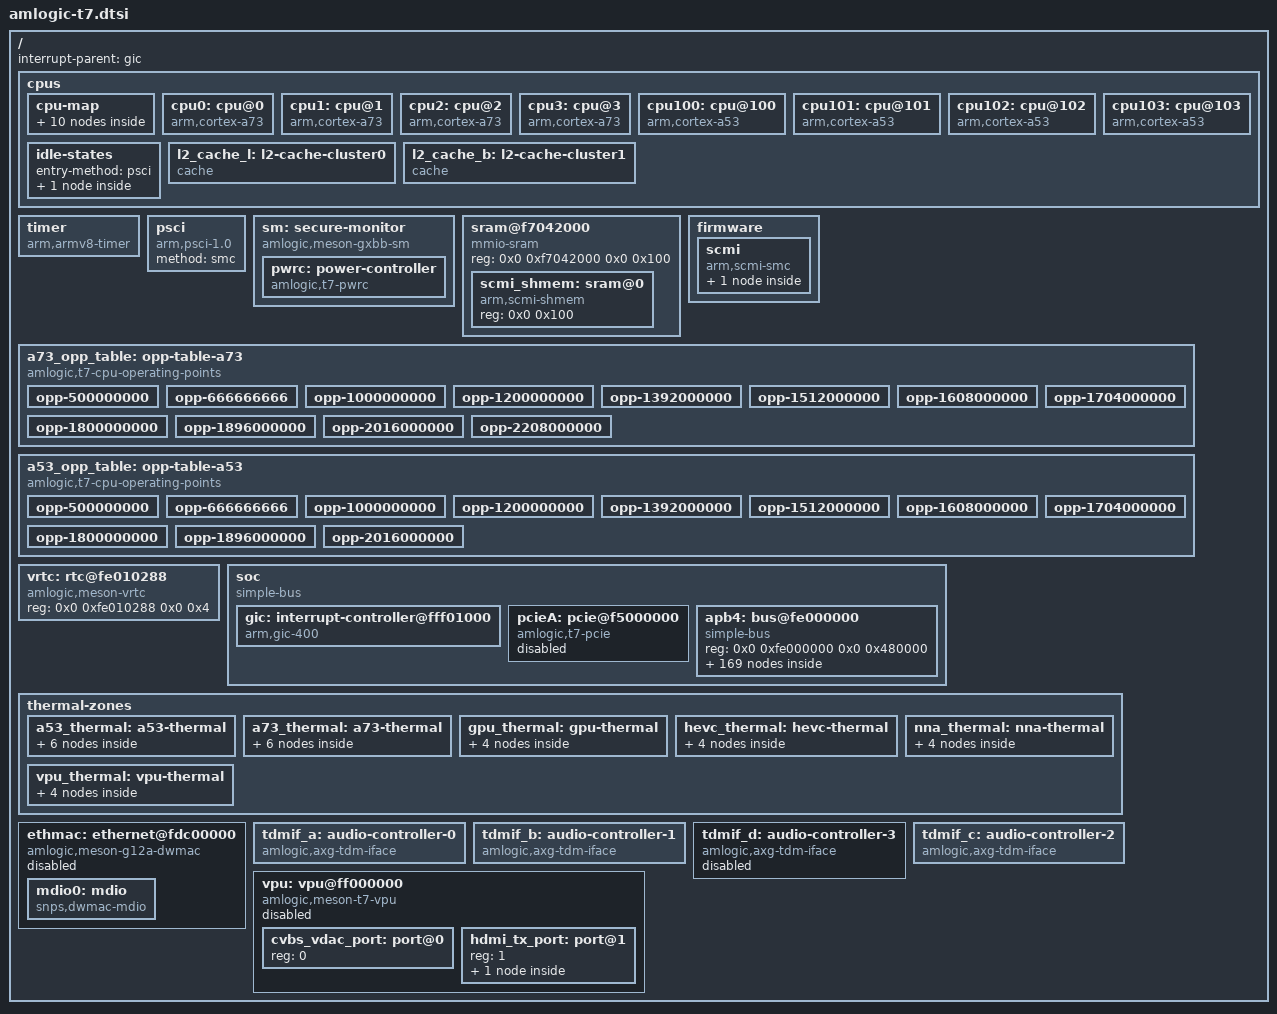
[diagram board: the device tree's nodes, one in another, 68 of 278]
// SPDX-License-Identifier: (GPL-2.0+ OR MIT)
/*
 * Copyright (c) 2019 Amlogic, Inc. All rights reserved.
 */

#include <dt-bindings/interrupt-controller/arm-gic.h>
#include <dt-bindings/gpio/gpio.h>
#include <dt-bindings/gpio/amlogic,t7-periphs-pinctrl.h>
#include <dt-bindings/power/amlogic,t7-pwrc.h>
#include "amlogic-t7-reset.h"
#include <dt-bindings/clock/amlogic,t7-scmi.h>
#include <dt-bindings/clock/amlogic,t7-cpu-clkc.h>
#include <dt-bindings/clock/amlogic,t7-pll-clkc.h>
#include <dt-bindings/clock/amlogic,t7-peripherals-clkc.h>
#include <dt-bindings/thermal/thermal.h>
#include <dt-bindings/phy/phy.h>
#include <dt-bindings/clock/axg-audio-clkc.h>
#include <dt-bindings/reset/amlogic,meson-axg-audio-arb.h>
#include <dt-bindings/reset/amlogic,meson-g12a-audio-reset.h>
#include <dt-bindings/sound/meson-g12a-tohdmitx.h>

/ {
	interrupt-parent = <&gic>;
	#address-cells = <2>;
	#size-cells = <2>;

	cpus {
		#address-cells = <0x2>;
		#size-cells = <0x0>;

		cpu-map {
			cluster0 {
				core0 {
					cpu = <&cpu0>;
				};
				core1 {
					cpu = <&cpu1>;
				};
				core2 {
					cpu = <&cpu2>;
				};
				core3 {
					cpu = <&cpu3>;
				};
			};

			cluster1 {
				core0 {
					cpu = <&cpu100>;
				};
				core1 {
					cpu = <&cpu101>;
				};
				core2 {
					cpu = <&cpu102>;
				};
				core3 {
					cpu = <&cpu103>;
				};
			};
		};

		cpu0: cpu@0 {
			device_type = "cpu";
			compatible = "arm,cortex-a73";
			reg = <0x0 0x0>;
			enable-method = "psci";
			cpu-idle-states = <&cpu_sleep>;
			clocks = <&cpu_clkc CLKID_A73_CPU>;
			capacity-dmips-mhz = <1024>;
			dynamic-power-coefficient = <550>;
			d-cache-line-size = <64>;
			d-cache-size = <0x10000>;
			d-cache-sets = <64>;
			i-cache-line-size = <64>;
			i-cache-size = <0x10000>;
			i-cache-sets = <64>;
			next-level-cache = <&l2_cache_b>;
			#cooling-cells = <2>;
		};

		cpu1: cpu@1 {
			device_type = "cpu";
			compatible = "arm,cortex-a73";
			reg = <0x0 0x1>;
			enable-method = "psci";
			cpu-idle-states = <&cpu_sleep>;
			clocks = <&cpu_clkc CLKID_A73_CPU>;
			capacity-dmips-mhz = <1024>;
			dynamic-power-coefficient = <550>;
			d-cache-line-size = <64>;
			d-cache-size = <0x10000>;
			d-cache-sets = <64>;
			i-cache-line-size = <64>;
			i-cache-size = <0x10000>;
			i-cache-sets = <64>;
			next-level-cache = <&l2_cache_b>;
			#cooling-cells = <2>;
		};

		cpu2: cpu@2 {
			device_type = "cpu";
			compatible = "arm,cortex-a73";
			reg = <0x0 0x2>;
			enable-method = "psci";
			cpu-idle-states = <&cpu_sleep>;
			clocks = <&cpu_clkc CLKID_A73_CPU>;
			capacity-dmips-mhz = <1024>;
			dynamic-power-coefficient = <550>;
			d-cache-line-size = <64>;
			d-cache-size = <0x10000>;
			d-cache-sets = <64>;
			i-cache-line-size = <64>;
			i-cache-size = <0x10000>;
			i-cache-sets = <64>;
			next-level-cache = <&l2_cache_b>;
			#cooling-cells = <2>;
		};

		cpu3: cpu@3 {
			device_type = "cpu";
			compatible = "arm,cortex-a73";
			reg = <0x0 0x3>;
			enable-method = "psci";
			cpu-idle-states = <&cpu_sleep>;
			clocks = <&cpu_clkc CLKID_A73_CPU>;
			capacity-dmips-mhz = <1024>;
			dynamic-power-coefficient = <550>;
			d-cache-line-size = <64>;
			d-cache-size = <0x10000>;
			d-cache-sets = <64>;
			i-cache-line-size = <64>;
			i-cache-size = <0x10000>;
			i-cache-sets = <64>;
			next-level-cache = <&l2_cache_b>;
			#cooling-cells = <2>;
		};

		cpu100: cpu@100 {
			device_type = "cpu";
			compatible = "arm,cortex-a53";
			reg = <0x0 0x100>;
			enable-method = "psci";
			cpu-idle-states = <&cpu_sleep>;
			clocks = <&cpu_clkc CLKID_A53_CPU>;
			capacity-dmips-mhz = <632>;
			dynamic-power-coefficient = <110>;
			d-cache-line-size = <32>;
			d-cache-size = <0x8000>;
			d-cache-sets = <32>;
			i-cache-line-size = <32>;
			i-cache-size = <0x8000>;
			i-cache-sets = <32>;
			next-level-cache = <&l2_cache_l>;
			#cooling-cells = <2>;
		};

		cpu101: cpu@101 {
			device_type = "cpu";
			compatible = "arm,cortex-a53";
			reg = <0x0 0x101>;
			enable-method = "psci";
			cpu-idle-states = <&cpu_sleep>;
			clocks = <&cpu_clkc CLKID_A53_CPU>;
			capacity-dmips-mhz = <632>;
			dynamic-power-coefficient = <110>;
			d-cache-line-size = <32>;
			d-cache-size = <0x8000>;
			d-cache-sets = <32>;
			i-cache-line-size = <32>;
			i-cache-size = <0x8000>;
			i-cache-sets = <32>;
			next-level-cache = <&l2_cache_l>;
			#cooling-cells = <2>;
		};

		cpu102: cpu@102 {
			device_type = "cpu";
			compatible = "arm,cortex-a53";
			reg = <0x0 0x102>;
			enable-method = "psci";
			cpu-idle-states = <&cpu_sleep>;
			clocks = <&cpu_clkc CLKID_A53_CPU>;
			capacity-dmips-mhz = <632>;
			dynamic-power-coefficient = <110>;
			d-cache-line-size = <32>;
			d-cache-size = <0x8000>;
			d-cache-sets = <32>;
			i-cache-line-size = <32>;
			i-cache-size = <0x8000>;
			i-cache-sets = <32>;
			next-level-cache = <&l2_cache_l>;
			#cooling-cells = <2>;
		};

		cpu103: cpu@103 {
			device_type = "cpu";
			compatible = "arm,cortex-a53";
			reg = <0x0 0x103>;
			enable-method = "psci";
			cpu-idle-states = <&cpu_sleep>;
			clocks = <&cpu_clkc CLKID_A53_CPU>;
			capacity-dmips-mhz = <632>;
			dynamic-power-coefficient = <110>;
			d-cache-line-size = <32>;
			d-cache-size = <0x8000>;
			d-cache-sets = <32>;
			i-cache-line-size = <32>;
			i-cache-size = <0x8000>;
			i-cache-sets = <32>;
			next-level-cache = <&l2_cache_l>;
			#cooling-cells = <2>;
		};

		idle-states {
			entry-method = "psci";

			cpu_sleep: cpu-sleep {
				compatible = "arm,idle-state";
				/* Power-down entry/exit has not been verified on VIM4. */
				status = "disabled";
				arm,psci-suspend-param = <0x10000>;
				local-timer-stop;
				entry-latency-us = <4000>;
				exit-latency-us = <5000>;
				min-residency-us = <10000>;
			};
		};

		l2_cache_l: l2-cache-cluster0 {
			compatible = "cache";
			cache-level = <2>;
			cache-unified;
			cache-size = <0x40000>;  /* L2. 256 KB */
			cache-line-size = <64>;
			cache-sets = <512>;
		};

		l2_cache_b: l2-cache-cluster1 {
			compatible = "cache";
			cache-level = <2>;
			cache-unified;
			cache-size = <0x100000>; /* L2. 1 Mb */
			cache-line-size = <64>;
			cache-sets = <512>;
		};
	};

	timer {
		compatible = "arm,armv8-timer";
		interrupts = <GIC_PPI 13 (GIC_CPU_MASK_SIMPLE(8) | IRQ_TYPE_LEVEL_LOW)>,
			     <GIC_PPI 14 (GIC_CPU_MASK_SIMPLE(8) | IRQ_TYPE_LEVEL_LOW)>,
			     <GIC_PPI 11 (GIC_CPU_MASK_SIMPLE(8) | IRQ_TYPE_LEVEL_LOW)>,
			     <GIC_PPI 10 (GIC_CPU_MASK_SIMPLE(8) | IRQ_TYPE_LEVEL_LOW)>;
	};

	psci {
		compatible = "arm,psci-1.0";
		method = "smc";
	};

	sm: secure-monitor {
		compatible = "amlogic,meson-gxbb-sm";

		pwrc: power-controller {
			compatible = "amlogic,t7-pwrc";
			#power-domain-cells = <1>;
		};
	};

	sram@f7042000 {
		compatible = "mmio-sram";
		reg = <0x0 0xf7042000 0x0 0x100>;
		#address-cells = <1>;
		#size-cells = <1>;
		ranges = <0 0x0 0xf7042000 0x100>;

		scmi_shmem: sram@0 {
			compatible = "arm,scmi-shmem";
			reg = <0x0 0x100>;
		};
	};

	firmware {
		scmi: scmi {
			compatible = "arm,scmi-smc";
			arm,smc-id = <0x820000c1>;
			shmem = <&scmi_shmem>;
			#address-cells = <1>;
			#size-cells = <0>;

			scmi_clk: protocol@14 {
				reg = <0x14>;
				#clock-cells = <1>;
			};
		};
	};

	a73_opp_table: opp-table-a73 {
		compatible = "amlogic,t7-cpu-operating-points";
		amlogic,secure-monitor = <&sm>;
		opp-shared;

		opp-500000000 {
			opp-hz = /bits/ 64 <500000000>;
			opp-microvolt = <819000>;
			opp-microvolt-bin2 = <799000>;
			opp-microvolt-bin3 = <789000>;
			clock-latency-ns = <50000>;
		};

		opp-666666666 {
			opp-hz = /bits/ 64 <666666666>;
			opp-microvolt = <819000>;
			opp-microvolt-bin2 = <799000>;
			opp-microvolt-bin3 = <789000>;
			clock-latency-ns = <50000>;
		};

		opp-1000000000 {
			opp-hz = /bits/ 64 <1000000000>;
			opp-microvolt = <819000>;
			opp-microvolt-bin2 = <799000>;
			opp-microvolt-bin3 = <789000>;
			clock-latency-ns = <50000>;
		};

		opp-1200000000 {
			opp-hz = /bits/ 64 <1200000000>;
			opp-microvolt = <819000>;
			opp-microvolt-bin2 = <799000>;
			opp-microvolt-bin3 = <789000>;
			clock-latency-ns = <50000>;
		};

		opp-1392000000 {
			opp-hz = /bits/ 64 <1392000000>;
			opp-microvolt = <819000>;
			opp-microvolt-bin2 = <809000>;
			opp-microvolt-bin3 = <809000>;
			clock-latency-ns = <50000>;
		};

		opp-1512000000 {
			opp-hz = /bits/ 64 <1512000000>;
			opp-microvolt = <829000>;
			opp-microvolt-bin2 = <809000>;
			opp-microvolt-bin3 = <809000>;
			clock-latency-ns = <50000>;
		};

		opp-1608000000 {
			opp-hz = /bits/ 64 <1608000000>;
			opp-microvolt = <849000>;
			opp-microvolt-bin2 = <829000>;
			opp-microvolt-bin3 = <819000>;
			clock-latency-ns = <50000>;
		};

		opp-1704000000 {
			opp-hz = /bits/ 64 <1704000000>;
			opp-microvolt = <869000>;
			opp-microvolt-bin2 = <849000>;
			opp-microvolt-bin3 = <829000>;
			clock-latency-ns = <50000>;
		};

		opp-1800000000 {
			opp-hz = /bits/ 64 <1800000000>;
			opp-microvolt = <909000>;
			opp-microvolt-bin2 = <859000>;
			opp-microvolt-bin3 = <849000>;
			clock-latency-ns = <50000>;
		};

		opp-1896000000 {
			opp-hz = /bits/ 64 <1896000000>;
			opp-microvolt = <939000>;
			opp-microvolt-bin2 = <889000>;
			opp-microvolt-bin3 = <859000>;
			clock-latency-ns = <50000>;
		};

		opp-2016000000 {
			opp-hz = /bits/ 64 <2016000000>;
			opp-microvolt = <959000>;
			opp-microvolt-bin2 = <919000>;
			opp-microvolt-bin3 = <879000>;
			clock-latency-ns = <50000>;
		};

		opp-2208000000 {
			opp-hz = /bits/ 64 <2208000000>;
			opp-microvolt = <1009000>;
			opp-microvolt-bin2 = <969000>;
			opp-microvolt-bin3 = <919000>;
			clock-latency-ns = <50000>;
		};
	};

	a53_opp_table: opp-table-a53 {
		compatible = "amlogic,t7-cpu-operating-points";
		amlogic,secure-monitor = <&sm>;
		opp-shared;

		opp-500000000 {
			opp-hz = /bits/ 64 <500000000>;
			opp-microvolt = <769000>;
			opp-microvolt-bin2 = <759000>;
			opp-microvolt-bin3 = <749000>;
			clock-latency-ns = <50000>;
		};

		opp-666666666 {
			opp-hz = /bits/ 64 <666666666>;
			opp-microvolt = <769000>;
			opp-microvolt-bin2 = <759000>;
			opp-microvolt-bin3 = <749000>;
			clock-latency-ns = <50000>;
		};

		opp-1000000000 {
			opp-hz = /bits/ 64 <1000000000>;
			opp-microvolt = <769000>;
			opp-microvolt-bin2 = <759000>;
			opp-microvolt-bin3 = <749000>;
			clock-latency-ns = <50000>;
		};

		opp-1200000000 {
			opp-hz = /bits/ 64 <1200000000>;
			opp-microvolt = <769000>;
			opp-microvolt-bin2 = <759000>;
			opp-microvolt-bin3 = <749000>;
			clock-latency-ns = <50000>;
		};

		opp-1392000000 {
			opp-hz = /bits/ 64 <1392000000>;
			opp-microvolt = <769000>;
			opp-microvolt-bin2 = <769000>;
			opp-microvolt-bin3 = <769000>;
			clock-latency-ns = <50000>;
		};

		opp-1512000000 {
			opp-hz = /bits/ 64 <1512000000>;
			opp-microvolt = <809000>;
			opp-microvolt-bin2 = <789000>;
			opp-microvolt-bin3 = <779000>;
			clock-latency-ns = <50000>;
		};

		opp-1608000000 {
			opp-hz = /bits/ 64 <1608000000>;
			opp-microvolt = <839000>;
			opp-microvolt-bin2 = <799000>;
			opp-microvolt-bin3 = <789000>;
			clock-latency-ns = <50000>;
		};

		opp-1704000000 {
			opp-hz = /bits/ 64 <1704000000>;
			opp-microvolt = <869000>;
			opp-microvolt-bin2 = <829000>;
			opp-microvolt-bin3 = <809000>;
			clock-latency-ns = <50000>;
		};

		opp-1800000000 {
			opp-hz = /bits/ 64 <1800000000>;
			opp-microvolt = <909000>;
			opp-microvolt-bin2 = <859000>;
			opp-microvolt-bin3 = <829000>;
			clock-latency-ns = <50000>;
		};

		opp-1896000000 {
			opp-hz = /bits/ 64 <1896000000>;
			opp-microvolt = <949000>;
			opp-microvolt-bin2 = <899000>;
			opp-microvolt-bin3 = <859000>;
			clock-latency-ns = <50000>;
		};

		opp-2016000000 {
			opp-hz = /bits/ 64 <2016000000>;
			opp-microvolt = <1009000>;
			opp-microvolt-bin2 = <949000>;
			opp-microvolt-bin3 = <919000>;
			clock-latency-ns = <50000>;
		};
	};

	vrtc: rtc@fe010288 {
		compatible = "amlogic,meson-vrtc";
		reg = <0x0 0xfe010288 0x0 0x4>;
	};

	soc {
		compatible = "simple-bus";
		#address-cells = <2>;
		#size-cells = <2>;
		ranges;

		gic: interrupt-controller@fff01000 {
			compatible = "arm,gic-400";
			#interrupt-cells = <3>;
			#address-cells = <0>;
			interrupt-controller;
			reg = <0x0 0xfff01000 0 0x1000>,
			      <0x0 0xfff02000 0 0x2000>,
			      <0x0 0xfff04000 0 0x2000>,
			      <0x0 0xfff06000 0 0x2000>;
			interrupts = <GIC_PPI 9 (GIC_CPU_MASK_SIMPLE(8) | IRQ_TYPE_LEVEL_HIGH)>;
		};

		pcieA: pcie@f5000000 {
			compatible = "amlogic,t7-pcie", "snps,dw-pcie";
			reg = <0x0 0xf5000000 0x0 0x400000>,
			      <0x0 0xfe02c000 0x0 0x2000>,
			      <0x0 0xf5400000 0x0 0x200000>;
			reg-names = "dbi", "cfg", "config";
			interrupts = <GIC_SPI 141 IRQ_TYPE_LEVEL_HIGH>;
			interrupt-names = "msi";
			#interrupt-cells = <1>;
			interrupt-map-mask = <0 0 0 0>;
			interrupt-map = <0 0 0 0 &gic GIC_SPI 143 IRQ_TYPE_EDGE_RISING>;
			bus-range = <0x0 0xff>;
			#address-cells = <3>;
			#size-cells = <2>;
			device_type = "pci";
			ranges = <0x81000000 0x0 0x0 0x0 0xf5600000 0x0 0x100000>,
				 <0x82000000 0x0 0xf5700000 0x0 0xf5700000 0x0 0x1900000>;

			clocks = <&clkc_periphs CLKID_SYS_PCIE_PHY>, <&clkc_periphs CLKID_SYS_PCIE>,
				 <&pcie CLKID_PCIE_PLL>;
			clock-names = "general", "pclk", "port";
			power-domains = <&pwrc PWRC_T7_PCIE_ID>;
			resets = <&reset RESET_PCIE_A>,
				 <&reset RESET_PCIE_APB>;
			reset-names = "port",
				      "apb";

			dma-ranges = <0x02000000 0x0 0x0 0x0 0X0 0x0 0xe0000000>;
			num-lanes = <1>;
			phys = <&pcie_phy PHY_TYPE_PCIE>;
			phy-names = "pcie";
			status = "disabled";
		};

		apb4: bus@fe000000 {
			compatible = "simple-bus";
			reg = <0x0 0xfe000000 0x0 0x480000>;
			#address-cells = <2>;
			#size-cells = <2>;
			ranges = <0x0 0x0 0x0 0xfe000000 0x0 0x480000>,
				 <0x0 0xfdd00000 0x0 0xfdd00000 0x0 0x200000>; /* usb drd */

			rng: rng@440788 {
				compatible = "amlogic,meson-s4-rng";
				reg = <0x0 0x440788 0x0 0xc>;
			};

			clkc_periphs: clock-controller@0 {
				compatible = "amlogic,t7-peripherals-clkc";
				reg = <0x0 0x0 0x0 0x1c8>;
				#clock-cells = <1>;
				clocks = <&xtal>,
					 <&scmi_clk CLKID_SYS_CLK>,
					 <&scmi_clk CLKID_FIXED_PLL>,
					 <&scmi_clk CLKID_FCLK_DIV2>,
					 <&scmi_clk CLKID_FCLK_DIV2P5>,
					 <&scmi_clk CLKID_FCLK_DIV3>,
					 <&scmi_clk CLKID_FCLK_DIV4>,
					 <&scmi_clk CLKID_FCLK_DIV5>,
					 <&scmi_clk CLKID_FCLK_DIV7>,
					 <&hifi CLKID_HIFI_PLL>,
					 <&gp0 CLKID_GP0_PLL>,
					 <&gp1 CLKID_GP1_PLL>,
					 <&mpll CLKID_MPLL1>,
					 <&mpll CLKID_MPLL2>,
					 <&mpll CLKID_MPLL3>;
				clock-names = "xtal",
					      "sys",
					      "fix",
					      "fdiv2",
					      "fdiv2p5",
					      "fdiv3",
					      "fdiv4",
					      "fdiv5",
					      "fdiv7",
					      "hifi",
					      "gp0",
					      "gp1",
					      "mpll1",
					      "mpll2",
					      "mpll3";
			};

			reset: reset-controller@2000 {
				compatible = "amlogic,t7-reset";
				reg = <0x0 0x2000 0x0 0x98>;
				#reset-cells = <1>;
			};

			watchdog@2100 {
				compatible = "amlogic,t7-wdt";
				reg = <0x0 0x2100 0x0 0x10>;
				clocks = <&xtal>;
			};

			saradc: adc@26000 {
				compatible = "amlogic,meson-g12a-saradc",
					     "amlogic,meson-saradc";
				reg = <0x0 0x26000 0x0 0x48>;
				interrupts = <GIC_SPI 181 IRQ_TYPE_EDGE_RISING>;
				#io-channel-cells = <1>;
				clocks = <&xtal>, <&clkc_periphs CLKID_SYS_SAR_ADC>,
					 <&clkc_periphs CLKID_SARADC>,
					 <&clkc_periphs CLKID_SARADC_SEL>;
				clock-names = "clkin", "core", "adc_clk", "adc_sel";
				status = "disabled";
			};

			spifc: spi@56000 {
				compatible = "amlogic,meson-gxbb-spifc";
				reg = <0x0 0x56000 0x0 0x80>;
				clocks = <&clkc_periphs CLKID_SYS_SPIFC>;
				#address-cells = <1>;
				#size-cells = <0>;
				status = "disabled";
			};

			ir: ir-receiver@84040 {
				compatible = "amlogic,meson-gxbb-ir";
				reg = <0x0 0x84040 0x0 0xa4>;
				interrupts = <GIC_SPI 22 IRQ_TYPE_EDGE_RISING>;
				status = "disabled";
			};

			periphs_pinctrl: pinctrl@4000 {
				compatible = "amlogic,t7-periphs-pinctrl";
				#address-cells = <2>;
				#size-cells = <2>;
				ranges;

				gpio: bank@4000 {
					reg = <0x0 0x4000 0x0 0x0064>,
					      <0x0 0x40c0 0x0 0x0220>;
					reg-names = "mux", "gpio";
					gpio-controller;
					#gpio-cells = <2>;
					gpio-ranges = <&periphs_pinctrl 0 0 157>;
				};

				emmc_ctrl_pins: emmc-ctrl {
					mux-0 {
						groups = "emmc_cmd";
						function = "emmc";
						bias-pull-up;
					};

					mux-1 {
						groups = "emmc_clk";
						function = "emmc";
						bias-disable;
					};
				};

				emmc_data_4b_pins: emmc-data-4b {
					mux {
						groups = "emmc_nand_d0",
							 "emmc_nand_d1",
							 "emmc_nand_d2",
							 "emmc_nand_d3";
						function = "emmc";
						bias-pull-up;
					};
				};

				emmc_data_8b_pins: emmc-data-8b {
					mux {
						groups = "emmc_nand_d0",
							 "emmc_nand_d1",
							 "emmc_nand_d2",
							 "emmc_nand_d3",
							 "emmc_nand_d4",
							 "emmc_nand_d5",
							 "emmc_nand_d6",
							 "emmc_nand_d7";
						function = "emmc";
						bias-pull-up;
					};
				};

				emmc_ds_pins: emmc-ds {
					mux {
						groups = "emmc_nand_ds";
						function = "emmc";
						bias-pull-down;
					};
				};

				emmc_clk_gate_pins: emmc-clk-gate {
					mux {
						groups = "GPIOB_8";
						function = "gpio_periphs";
						bias-pull-down;
					};
				};

				i2c0_ao_d_pins: i2c0-ao-d {
					mux {
						groups = "i2c0_ao_sck_d",
							 "i2c0_ao_sda_d";
						function = "i2c0_ao";
						bias-disable;
						drive-strength-microamp = <3000>;
					};
				};

				pwm_a_pins: pwm-a {
					mux {
						groups = "pwm_a";
						function = "pwm_a";
						bias-disable;
					};
				};

				pwm_ao_a_pins: pwm-ao-a {
					mux {
						groups = "pwm_ao_a";
						function = "pwm_ao_a";
						bias-disable;
					};
				};

				pwm_ao_b_pins: pwm-ao-b {
					mux {
						groups = "pwm_ao_b";
						function = "pwm_ao_b";
						bias-disable;
					};
				};

				pwm_ao_c_d_pins: pwm-ao-c-d {
					mux {
						groups = "pwm_ao_c_d";
						function = "pwm_ao_c";
						bias-disable;
					};
				};

				pwm_ao_c_e_pins: pwm-ao-c-e {
					mux {
						groups = "pwm_ao_c_e";
						function = "pwm_ao_c";
						bias-disable;
					};
				};

				pwm_ao_c_hiz_pins: pwm-ao-c-hiz {
					mux {
						groups = "pwm_ao_c_hiz";
						function = "pwm_ao_c_hiz";
						bias-disable;
					};
				};

				pwm_ao_d_pins: pwm-ao-d {
					mux {
						groups = "pwm_ao_d";
						function = "pwm_ao_d";
						bias-disable;
					};
				};

				pwm_ao_e_pins: pwm-ao-e {
					mux {
						groups = "pwm_ao_e";
						function = "pwm_ao_e";
						bias-disable;
					};
				};

				pwm_ao_f_pins: pwm-ao-f {
					mux {
						groups = "pwm_ao_f";
						function = "pwm_ao_f";
						bias-disable;
					};
				};

				pwm_ao_g_d11_pins: pwm-ao-g-d11 {
					mux {
						groups = "pwm_ao_g_d11";
						function = "pwm_ao_g";
						bias-disable;
					};
				};

				pwm_ao_g_d7_pins: pwm-ao-g-d7 {
					mux {
						groups = "pwm_ao_g_d7";
						function = "pwm_ao_g";
						bias-disable;
					};
				};

				pwm_ao_g_e_pins: pwm-ao-g-e {
					mux {
						groups = "pwm_ao_g_e";
						function = "pwm_ao_g";
						bias-disable;
					};
				};

				pwm_ao_g_hiz_pins: pwm-ao-g-hiz {
					mux {
						groups = "pwm_ao_g_hiz";
						function = "pwm_ao_g_hiz";
						bias-disable;
					};
				};

				pwm_ao_h_d5_pins: pwm-ao-h-d5 {
					mux {
						groups = "pwm_ao_h_d5";
						function = "pwm_ao_h";
						bias-disable;
					};
				};

				pwm_ao_h_d10_pins: pwm-ao-h-d10 {
					mux {
						groups = "pwm_ao_h_d10";
						function = "pwm_ao_h";
						bias-disable;
					};
				};

				pwm_b_pins: pwm-b {
					mux {
						groups = "pwm_b";
						function = "pwm_b";
						bias-disable;
					};
				};

				pwm_c_pins: pwm-c {
					mux {
						groups = "pwm_c";
						function = "pwm_c";
						bias-disable;
					};
				};

				pwm_d_pins: pwm-d {
					mux {
						groups = "pwm_d";
						function = "pwm_d";
						bias-disable;
					};
				};

				pwm_e_pins: pwm-e {
					mux {
						groups = "pwm_e";
						function = "pwm_e";
						bias-disable;
					};
				};

				pwm_f_pins: pwm-f {
					mux {
						groups = "pwm_f";
						function = "pwm_f";
						bias-disable;
					};
				};

				pwm_vs_y_pins: pwm-vs-y {
					mux {
						groups = "pwm_vs_y";
						function = "pwm_vs";
						bias-disable;
					};
				};

				pwm_vs_h_pins: pwm-vs-h {
					mux {
						groups = "pwm_vs_h";
						function = "pwm_vs";
						bias-disable;
					};
				};

				sdcard_pins: sdcard {
					mux {
						groups = "sdcard_d0",
							 "sdcard_d1",
							 "sdcard_d2",
							 "sdcard_d3",
							 "sdcard_clk",
							 "sdcard_cmd";
						function = "sdcard";
						bias-pull-up;
					};
				};

				sdcard_clk_gate_pins: sdcard-clk-gate {
					mux {
						groups = "GPIOC_4";
						function = "gpio_periphs";
						bias-pull-down;
					};
				};

				uart_c_pins: uart-c {
					mux {
						groups = "uart_c_tx",
							 "uart_c_rx",
							 "uart_c_cts",
							 "uart_c_rts";
						bias-pull-up;
						output-high;
						function = "uart_c";
					};
				};

				sdio_pins: sdio {
					mux {
						groups = "sdio_d0",
							 "sdio_d1",
							 "sdio_d2",
							 "sdio_d3",
							 "sdio_clk",
							 "sdio_cmd";
						function = "sdio";
						bias-pull-up;
					};
				};

				sdio_clk_gate_pins: sdio-clk-gate {
					mux {
						groups = "GPIOX_4";
						function = "gpio_periphs";
						bias-pull-up;
					};
				};

				eth_pins: eth {
					mux {
						groups = "eth_mdio",
							 "eth_mdc",
							 "eth_rgmii_rx_clk",
							 "eth_rx_dv",
							 "eth_rxd0",
							 "eth_rxd1",
							 "eth_txen",
							 "eth_txd0",
							 "eth_txd1";
						function = "eth";
						drive-strength-microamp = <4000>;
						bias-disable;
					};
				};

				eth_rgmii_pins: eth-rgmii {
					mux {
						groups = "eth_rxd2_rgmii",
							 "eth_rxd3_rgmii",
							 "eth_rgmii_tx_clk",
							 "eth_txd2_rgmii",
							 "eth_txd3_rgmii";
						function = "eth";
						drive-strength-microamp = <4000>;
						bias-disable;
					};
				};
			};

			gpio_intc: interrupt-controller@4080 {
				compatible = "amlogic,t7-gpio-intc",
					     "amlogic,meson-gpio-intc";
				reg = <0x0 0x4080 0x0 0x20>;
				interrupt-controller;
				#interrupt-cells = <2>;
				amlogic,channel-interrupts =
					<10 11 12 13 14 15 16 17 18 19 20 21>;
			};

			usb_comb: usb@3a000 {
				compatible = "amlogic,t7-usb-ctrl", "amlogic,meson-g12a-usb-ctrl";
				reg = <0x0 0x3a000 0x0 0xa0>;
				interrupts = <GIC_SPI 129 IRQ_TYPE_LEVEL_HIGH>;
				#address-cells = <2>;
				#size-cells = <2>;
				ranges = <0x0 0xfdd00000 0x0 0xfdd00000 0x0 0x200000>;

				clocks = <&clkc_periphs CLKID_SYS_USB>;
				resets = <&reset RESET_USB>;
				power-domains = <&pwrc PWRC_T7_USB_COMB_ID>;

				dr_mode = "otg";

				phys = <&usb2_phy0>, <&usb2_phy1>, <&usb3_phy PHY_TYPE_USB3>;
				phy-names = "usb2-phy0", "usb2-phy1", "usb3-phy0";

				status = "disabled";

				usb2_drd: usb@fdd00000 {
					compatible = "amlogic,t7-xhci";
					reg = <0x0 0xfdd00000 0x0 0x100000>;
					interrupts = <GIC_SPI 131 IRQ_TYPE_LEVEL_HIGH>;
					clocks = <&clkc_periphs CLKID_SYS_USB>;
					clock-names = "core";
				};

				usb3_drd: usb@fde00000 {
					compatible = "amlogic,t7-xhci";
					reg = <0x0 0xfde00000 0x0 0x100000>;
					interrupts = <GIC_SPI 130 IRQ_TYPE_LEVEL_HIGH>;
					clocks = <&clkc_periphs CLKID_SYS_USB>;
					clock-names = "core";
				};
			};

			usb2_phy0: phy@3c000 {
				compatible = "amlogic,t7-usb2-phy", "amlogic,g12a-usb2-phy";
				reg = <0x0 0x3c000 0x0 0x2000>;
				clocks = <&xtal>;
				clock-names = "xtal";
				resets = <&reset RESET_U2PHY20>;
				reset-names = "phy";
				#phy-cells = <0>;
			};

			usb2_phy1: phy@3e000 {
				compatible = "amlogic,t7-usb2-phy", "amlogic,g12a-usb2-phy";
				reg = <0x0 0x3e000 0x0 0x2000>;
				clocks = <&xtal>;
				clock-names = "xtal";
				resets = <&reset RESET_U2PHY21>;
				reset-names = "phy";
				#phy-cells = <0>;
			};

			usb3_phy: phy@62000 {
				compatible = "amlogic,t7-usb3-phy", "amlogic,g12a-usb3-pcie-phy";
				reg = <0x0 0x62000 0x0 0x2000>;
				clocks = <&pcie CLKID_PCIE_PLL>;
				clock-names = "ref_clk";
				resets = <&reset RESET_PCIE1_APB>;
				reset-names = "phy";
				assigned-clocks = <&pcie CLKID_PCIE_PLL>;
				assigned-clock-rates = <100000000>;
				#phy-cells = <1>;
			};

			uart_a: serial@78000 {
				compatible = "amlogic,t7-uart", "amlogic,meson-s4-uart";
				reg = <0x0 0x78000 0x0 0x18>;
				interrupts = <GIC_SPI 168 IRQ_TYPE_EDGE_RISING>;
				status = "disabled";
			};

			uart_c: serial@7c000 {
				compatible = "amlogic,t7-uart", "amlogic,meson-s4-uart";
				reg = <0x0 0x7c000 0x0 0x18>;
				interrupts = <GIC_SPI 170 IRQ_TYPE_EDGE_RISING>;
				clocks = <&xtal>, <&clkc_periphs CLKID_SYS_UART_C>, <&xtal>;
				clock-names = "xtal", "pclk", "baud";
				status = "disabled";
			};

			gpu: gpu@400000 {
				compatible = "amlogic,meson-g12a-mali", "arm,mali-bifrost";
				reg = <0x0 0x400000 0x0 0x4000>;
				interrupts = <GIC_SPI 146 IRQ_TYPE_LEVEL_HIGH>,
					     <GIC_SPI 145 IRQ_TYPE_LEVEL_HIGH>,
					     <GIC_SPI 144 IRQ_TYPE_LEVEL_HIGH>;
				interrupt-names = "job", "mmu", "gpu";
				clocks = <&clkc_periphs CLKID_MALI>,
					 <&clkc_periphs CLKID_SYS_MALI>;
				clock-names = "core", "bus";
				resets = <&reset RESET_MALI_CAPB3>, <&reset RESET_MALI>;
				power-domains = <&pwrc PWRC_T7_MALI_TOP_ID>;
				assigned-clocks = <&clkc_periphs CLKID_MALI_0_SEL>,
						  <&clkc_periphs CLKID_MALI_0>,
						  <&clkc_periphs CLKID_MALI>;
				assigned-clock-parents = <&scmi_clk CLKID_FCLK_DIV2P5>,
							 <0>,
							 <&clkc_periphs CLKID_MALI_0>;
				assigned-clock-rates = <0>, <800000000>, <0>;
				/* The GPU is IO-coherent (ACE-Lite) on T7 */
				dma-coherent;
				#cooling-cells = <2>;
				status = "disabled";
			};

			eth_phy: mdio-multiplexer@28000 {
				compatible = "amlogic,g12a-mdio-mux";
				reg = <0x0 0x28000 0x0 0xa4>;
				#address-cells = <1>;
				#size-cells = <0>;
				clocks = <&clkc_periphs CLKID_SYS_ETHPHY>,
					 <&xtal>,
					 <&scmi_clk CLKID_FCLK_50M>;
				clock-names = "pclk", "clkin0", "clkin1";
				mdio-parent-bus = <&mdio0>;

				ext_mdio: mdio@0 {
					reg = <0>;
					#address-cells = <1>;
					#size-cells = <0>;
				};

				int_mdio: mdio@1 {
					reg = <1>;
					#address-cells = <1>;
					#size-cells = <0>;

					internal_ephy: ethernet-phy@8 {
						compatible = "ethernet-phy-id0180.3301",
							     "ethernet-phy-ieee802.3-c22";
						interrupts = <GIC_SPI 340 IRQ_TYPE_LEVEL_HIGH>;
						reg = <8>;
						max-speed = <100>;
					};
				};
			};

			cpu_clkc: clock-controller@8000 {
				compatible = "amlogic,t7-cpu-clkc";
				reg = <0x0 0x8000 0x0 0x40>;
				clocks = <&xtal>,
					 <&scmi_clk CLKID_FCLK_DIV2>,
					 <&scmi_clk CLKID_FCLK_DIV3>,
					 <&scmi_clk CLKID_FCLK_DIV2P5>;
				clock-names = "xtal", "fclk_div2", "fclk_div3",
					      "fclk_div2p5";
				amlogic,secure-monitor = <&sm>;
				#clock-cells = <1>;
			};

			gp0: clock-controller@8080 {
				compatible = "amlogic,t7-gp0-pll";
				reg = <0x0 0x8080 0x0 0x20>;
				clocks = <&scmi_clk CLKID_TOP_PLL_OSC>;
				clock-names = "in0";
				#clock-cells = <1>;
			};

			gp1: clock-controller@80c0 {
				compatible = "amlogic,t7-gp1-pll";
				reg = <0x0 0x80c0 0x0 0x14>;
				clocks = <&scmi_clk CLKID_TOP_PLL_OSC>;
				clock-names = "in0";
				#clock-cells = <1>;
			};

			hifi: clock-controller@8100 {
				compatible = "amlogic,t7-hifi-pll";
				reg = <0x0 0x8100 0x0 0x20>;
				clocks = <&scmi_clk CLKID_TOP_PLL_OSC>;
				clock-names = "in0";
				#clock-cells = <1>;
			};

			pcie: clock-controller@8140 {
				compatible = "amlogic,t7-pcie-pll";
				reg = <0x0 0x8140 0x0 0x1c>;
				clocks = <&scmi_clk CLKID_PCIE_OSC>;
				clock-names = "in0";
				#clock-cells = <1>;
			};

			mpll: clock-controller@8180 {
				compatible = "amlogic,t7-mpll";
				reg = <0x0 0x8180 0x0 0x28>;
				clocks = <&scmi_clk CLKID_FIXED_PLL_DCO>;
				clock-names = "in0";
				#clock-cells = <1>;
			};

			hdmi: clock-controller@81c0 {
				compatible = "amlogic,t7-hdmi-pll";
				reg = <0x0 0x81c0 0x0 0x20>;
				clocks = <&scmi_clk CLKID_HDMI_PLL_OSC>;
				clock-names = "in0";
				#clock-cells = <1>;
			};

			mclk: clock-controller@8300 {
				compatible = "amlogic,t7-mclk-pll";
				reg = <0x0 0x8300 0x0 0x18>;
				clocks = <&scmi_clk CLKID_MCLK_PLL_OSC>,
					 <&xtal>,
					 <&scmi_clk CLKID_FCLK_50M>;
				clock-names = "in0", "in1", "in2";
				#clock-cells = <1>;
			};

			sec_ao: ao-secure@10220 {
				compatible = "amlogic,t7-ao-secure",
					     "amlogic,meson-gx-ao-secure",
					     "syscon";
				reg = <0x0 0x10220 0x0 0x140>;
				amlogic,has-chip-id;
			};

			a73_tsensor: temperature-sensor@20000 {
				compatible = "amlogic,t7-thermal";
				reg = <0x0 0x20000 0x0 0x50>;
				interrupts = <GIC_SPI 31 IRQ_TYPE_LEVEL_HIGH>;
				clocks = <&clkc_periphs CLKID_SYS_TS_A73>,
					 <&clkc_periphs CLKID_TS>;
				clock-names = "bus", "core";
				#thermal-sensor-cells = <0>;
				amlogic,secure-monitor = <&sm 1>;
			};

			a53_tsensor: temperature-sensor@22000 {
				compatible = "amlogic,t7-thermal";
				reg = <0x0 0x22000 0x0 0x50>;
				interrupts = <GIC_SPI 30 IRQ_TYPE_LEVEL_HIGH>;
				clocks = <&clkc_periphs CLKID_SYS_TS_A53>,
					 <&clkc_periphs CLKID_TS>;
				clock-names = "bus", "core";
				#thermal-sensor-cells = <0>;
				amlogic,secure-monitor = <&sm 2>;
			};

			pcie_phy: phy@2a000 {
				compatible = "amlogic,t7-pcie-phy", "amlogic,g12a-usb3-pcie-phy";
				reg = <0x0 0x2a000 0x0 0x2000>;
				clocks = <&pcie CLKID_PCIE_PLL>;
				clock-names = "ref_clk";
				resets = <&reset RESET_PCIE_PHY>;
				reset-names = "phy";
				assigned-clocks = <&pcie CLKID_PCIE_PLL>;
				assigned-clock-rates = <100000000>;
				#phy-cells = <1>;
			};

			pwm_ao_ef: pwm@30000 {
				compatible = "amlogic,t7-pwm", "amlogic,meson-s4-pwm";
				reg = <0x0 0x30000 0x0 0x24>;
				clocks = <&clkc_periphs CLKID_PWM_AO_E>,
					 <&clkc_periphs CLKID_PWM_AO_F>,
					 <&clkc_periphs CLKID_SYS_PWM_AO_EF>;
				clock-names = "channel-a", "channel-b", "bus";
				#pwm-cells = <3>;
				status = "disabled";
			};

			pwm_ao_gh: pwm@32000 {
				compatible = "amlogic,t7-pwm", "amlogic,meson-s4-pwm";
				reg = <0x0 0x32000 0x0 0x24>;
				clocks = <&clkc_periphs CLKID_PWM_AO_G>,
					 <&clkc_periphs CLKID_PWM_AO_H>,
					 <&clkc_periphs CLKID_SYS_PWM_AO_GH>;
				clock-names = "channel-a", "channel-b", "bus";
				#pwm-cells = <3>;
				status = "disabled";
			};

			clock-measurer@48000 {
				compatible = "amlogic,t7-clk-measure";
				reg = <0x0 0x48000 0x0 0x1c>;
			};

			pwm_ab: pwm@58000 {
				compatible = "amlogic,t7-pwm", "amlogic,meson-s4-pwm";
				reg = <0x0 0x58000 0x0 0x24>;
				clocks = <&clkc_periphs CLKID_PWM_A>,
					 <&clkc_periphs CLKID_PWM_B>,
					 <&clkc_periphs CLKID_SYS_PWM_AB>;
				clock-names = "channel-a", "channel-b", "bus";
				#pwm-cells = <3>;
				status = "disabled";
			};

			pwm_cd: pwm@5a000 {
				compatible = "amlogic,t7-pwm", "amlogic,meson-s4-pwm";
				reg = <0x0 0x5a000 0x0 0x24>;
				clocks = <&clkc_periphs CLKID_PWM_C>,
					 <&clkc_periphs CLKID_PWM_D>,
					 <&clkc_periphs CLKID_SYS_PWM_CD>;
				clock-names = "channel-a", "channel-b", "bus";
				#pwm-cells = <3>;
				status = "disabled";
			};

			pwm_ef: pwm@5c000 {
				compatible = "amlogic,t7-pwm", "amlogic,meson-s4-pwm";
				reg = <0x0 0x5c000 0x0 0x24>;
				clocks = <&clkc_periphs CLKID_PWM_E>,
					 <&clkc_periphs CLKID_PWM_F>,
					 <&clkc_periphs CLKID_SYS_PWM_EF>;
				clock-names = "channel-a", "channel-b", "bus";
				#pwm-cells = <3>;
				status = "disabled";
			};

			pwm_ao_ab: pwm@5e000 {
				compatible = "amlogic,t7-pwm", "amlogic,meson-s4-pwm";
				reg = <0x0 0x5e000 0x0 0x24>;
				clocks = <&clkc_periphs CLKID_PWM_AO_A>,
					 <&clkc_periphs CLKID_PWM_AO_B>,
					 <&clkc_periphs CLKID_SYS_PWM_AO_AB>;
				clock-names = "channel-a", "channel-b", "bus";
				#pwm-cells = <3>;
				status = "disabled";
			};

			pwm_ao_cd: pwm@60000 {
				compatible = "amlogic,t7-pwm", "amlogic,meson-s4-pwm";
				reg = <0x0 0x60000 0x0 0x24>;
				clocks = <&clkc_periphs CLKID_PWM_AO_C>,
					 <&clkc_periphs CLKID_PWM_AO_D>,
					 <&clkc_periphs CLKID_SYS_PWM_AO_CD>;
				clock-names = "channel-a", "channel-b", "bus";
				#pwm-cells = <3>;
				status = "disabled";
			};

			i2c_m_ao_a: i2c@76000 {
				compatible = "amlogic,t7-i2c", "amlogic,meson-axg-i2c";
				reg = <0x0 0x76000 0x0 0x48>;
				#address-cells = <1>;
				#size-cells = <0>;
				interrupts = <GIC_SPI 330 IRQ_TYPE_EDGE_RISING>;
				clocks = <&clkc_periphs CLKID_SYS_I2C_AO_A>;
				status = "disabled";
			};

			sd_emmc_a: mmc@88000 {
				compatible = "amlogic,t7-mmc", "amlogic,meson-axg-mmc";
				reg = <0x0 0x88000 0x0 0x800>;
				interrupts = <GIC_SPI 176 IRQ_TYPE_LEVEL_HIGH>;
				clocks = <&clkc_periphs CLKID_SYS_SD_EMMC_A>,
					 <&clkc_periphs CLKID_SD_EMMC_A>,
					 <&scmi_clk CLKID_FCLK_DIV2>,
					 <&clkc_periphs CLKID_SYS_AMPIPE_NAND>;
				clock-names = "core", "clkin0", "clkin1", "pipeline";
				resets = <&reset RESET_SD_EMMC_A>;
				assigned-clocks = <&clkc_periphs CLKID_SD_EMMC_A_SEL>;
				assigned-clock-parents = <&xtal>;
				status = "disabled";
			};

			sd_emmc_b: mmc@8a000 {
				compatible = "amlogic,t7-mmc", "amlogic,meson-axg-mmc";
				reg = <0x0 0x8a000 0x0 0x800>;
				interrupts = <GIC_SPI 177 IRQ_TYPE_EDGE_RISING>;
				clocks = <&clkc_periphs CLKID_SYS_SD_EMMC_B>,
					 <&clkc_periphs CLKID_SD_EMMC_B>,
					 <&scmi_clk CLKID_FCLK_DIV2>,
					 <&clkc_periphs CLKID_SYS_AMPIPE_NAND>;
				clock-names = "core", "clkin0", "clkin1", "pipeline";
				resets = <&reset RESET_SD_EMMC_B>;
				assigned-clocks = <&clkc_periphs CLKID_SD_EMMC_B_SEL>;
				assigned-clock-parents = <&xtal>;
				status = "disabled";
			};

			sd_emmc_c: mmc@8c000 {
				compatible = "amlogic,t7-mmc", "amlogic,meson-axg-mmc";
				reg = <0x0 0x8c000 0x0 0x800>;
				interrupts = <GIC_SPI 178 IRQ_TYPE_EDGE_RISING>;
				clocks = <&clkc_periphs CLKID_SYS_SD_EMMC_C>,
					 <&clkc_periphs CLKID_SD_EMMC_C>,
					 <&scmi_clk CLKID_FCLK_DIV2>,
					 <&clkc_periphs CLKID_SYS_AMPIPE_NAND>;
				clock-names = "core", "clkin0", "clkin1", "pipeline";
				resets = <&reset RESET_SD_EMMC_C>;
				assigned-clocks = <&clkc_periphs CLKID_SD_EMMC_C_SEL>;
				assigned-clock-parents = <&xtal>;
				status = "disabled";
			};

			gpu_tsensor: temperature-sensor@94000 {
				compatible = "amlogic,t7-thermal";
				reg = <0x0 0x94000 0x0 0x50>;
				interrupts = <GIC_SPI 83 IRQ_TYPE_LEVEL_HIGH>;
				clocks = <&clkc_periphs CLKID_SYS_TS_GPU>,
					 <&clkc_periphs CLKID_TS>;
				clock-names = "bus", "core";
				power-domains = <&pwrc PWRC_T7_MALI_TOP_ID>;
				#thermal-sensor-cells = <0>;
				amlogic,secure-monitor = <&sm 3>;
			};

			nna_tsensor: temperature-sensor@96000 {
				compatible = "amlogic,t7-thermal";
				reg = <0x0 0x96000 0x0 0x50>;
				interrupts = <GIC_SPI 84 IRQ_TYPE_LEVEL_HIGH>;
				clocks = <&clkc_periphs CLKID_SYS_TS_NNA>,
					 <&clkc_periphs CLKID_TS>;
				clock-names = "bus", "core";
				power-domains = <&pwrc PWRC_T7_NNA_TOP_ID>;
				#thermal-sensor-cells = <0>;
				amlogic,secure-monitor = <&sm 4>;
			};

			vpu_tsensor: temperature-sensor@98000 {
				compatible = "amlogic,t7-thermal";
				reg = <0x0 0x98000 0x0 0x50>;
				interrupts = <GIC_SPI 85 IRQ_TYPE_LEVEL_HIGH>;
				clocks = <&clkc_periphs CLKID_SYS_TS_VPU>,
					 <&clkc_periphs CLKID_TS>;
				clock-names = "bus", "core";
				power-domains = <&pwrc PWRC_T7_VPU_HDMI_ID>;
				#thermal-sensor-cells = <0>;
				amlogic,secure-monitor = <&sm 6>;
			};

			hevc_tsensor: temperature-sensor@9a000 {
				compatible = "amlogic,t7-thermal";
				reg = <0x0 0x9a000 0x0 0x50>;
				interrupts = <GIC_SPI 86 IRQ_TYPE_LEVEL_HIGH>;
				clocks = <&clkc_periphs CLKID_SYS_TS_HEVC>,
					 <&clkc_periphs CLKID_TS>;
				clock-names = "bus", "core";
				power-domains = <&pwrc PWRC_T7_DOS_HEVC_ID>;
				#thermal-sensor-cells = <0>;
				amlogic,secure-monitor = <&sm 5>;
			};
		};
	};

	thermal-zones {
		a53_thermal: a53-thermal {
			polling-delay = <1000>;
			polling-delay-passive = <100>;
			thermal-sensors = <&a53_tsensor>;

			trips {
				a53_passive: a53-passive {
					temperature = <85000>; /* millicelsius */
					hysteresis = <2000>; /* millicelsius */
					type = "passive";
				};

				a53_hot: a53-hot {
					temperature = <95000>; /* millicelsius */
					hysteresis = <2000>; /* millicelsius */
					type = "hot";
				};

				a53_critical: a53-critical {
					temperature = <110000>; /* millicelsius */
					hysteresis = <2000>; /* millicelsius */
					type = "critical";
				};
			};

			cooling-maps {
				map-a53 {
					trip = <&a53_passive>;
					cooling-device =
						<&cpu100 THERMAL_NO_LIMIT THERMAL_NO_LIMIT>,
						<&cpu101 THERMAL_NO_LIMIT THERMAL_NO_LIMIT>,
						<&cpu102 THERMAL_NO_LIMIT THERMAL_NO_LIMIT>,
						<&cpu103 THERMAL_NO_LIMIT THERMAL_NO_LIMIT>;
				};
			};
		};

		a73_thermal: a73-thermal {
			polling-delay = <1000>;
			polling-delay-passive = <100>;
			thermal-sensors = <&a73_tsensor>;

			trips {
				a73_passive: a73-passive {
					temperature = <85000>; /* millicelsius */
					hysteresis = <2000>; /* millicelsius */
					type = "passive";
				};

				a73_hot: a73-hot {
					temperature = <95000>; /* millicelsius */
					hysteresis = <2000>; /* millicelsius */
					type = "hot";
				};

				a73_critical: a73-critical {
					temperature = <110000>; /* millicelsius */
					hysteresis = <2000>; /* millicelsius */
					type = "critical";
				};
			};

			cooling-maps {
				map-a73 {
					trip = <&a73_passive>;
					cooling-device = <&cpu0 THERMAL_NO_LIMIT THERMAL_NO_LIMIT>,
							 <&cpu1 THERMAL_NO_LIMIT THERMAL_NO_LIMIT>,
							 <&cpu2 THERMAL_NO_LIMIT THERMAL_NO_LIMIT>,
							 <&cpu3 THERMAL_NO_LIMIT THERMAL_NO_LIMIT>;
				};
			};
		};

		gpu_thermal: gpu-thermal {
			polling-delay = <1000>;
			polling-delay-passive = <100>;
			thermal-sensors = <&gpu_tsensor>;

			trips {
				gpu_passive: gpu-passive {
					temperature = <95000>;
					hysteresis = <5000>;
					type = "passive";
				};

				gpu_hot: gpu-hot {
					temperature = <105000>;
					hysteresis = <5000>;
					type = "passive";
				};

				gpu_critical: gpu-critical {
					temperature = <115000>;
					hysteresis = <1000>;
					type = "critical";
				};
			};

		};

		hevc_thermal: hevc-thermal {
			polling-delay = <1000>;
			polling-delay-passive = <100>;
			thermal-sensors = <&hevc_tsensor>;

			trips {
				hevc_passive: hevc-passive {
					temperature = <95000>;
					hysteresis = <5000>;
					type = "passive";
				};

				hevc_hot: hevc-hot {
					temperature = <105000>;
					hysteresis = <5000>;
					type = "passive";
				};

				hevc_critical: hevc-critical {
					temperature = <115000>;
					hysteresis = <1000>;
					type = "critical";
				};
			};
		};

		nna_thermal: nna-thermal {
			polling-delay = <1000>;
			polling-delay-passive = <100>;
			thermal-sensors = <&nna_tsensor>;

			trips {
				nna_passive: nna-passive {
					temperature = <95000>;
					hysteresis = <5000>;
					type = "passive";
				};

				nna_hot: nna-hot {
					temperature = <105000>;
					hysteresis = <5000>;
					type = "passive";
				};

				nna_critical: nna-critical {
					temperature = <115000>;
					hysteresis = <1000>;
					type = "critical";
				};
			};
		};

		vpu_thermal: vpu-thermal {
			polling-delay = <1000>;
			polling-delay-passive = <100>;
			thermal-sensors = <&vpu_tsensor>;

			trips {
				vpu_passive: vpu-passive {
					temperature = <95000>;
					hysteresis = <5000>;
					type = "passive";
				};

				vpu_hot: vpu-hot {
					temperature = <105000>;
					hysteresis = <5000>;
					type = "passive";
				};

				vpu_critical: vpu-critical {
					temperature = <115000>;
					hysteresis = <1000>;
					type = "critical";
				};
			};
		};
	};

	ethmac: ethernet@fdc00000 {
		compatible = "amlogic,meson-g12a-dwmac",
					"snps,dwmac-4.00",
					"snps,dwmac";
		reg = <0x0 0xfdc00000 0x0 0x10000>,
				<0x0 0xfe024000 0x0 0x8>;
		interrupts = <GIC_SPI 74 IRQ_TYPE_LEVEL_HIGH>;
		interrupt-names = "macirq";
		power-domains = <&pwrc PWRC_T7_ETH_ID>;
		clocks = <&clkc_periphs CLKID_SYS_ETH>,
				<&scmi_clk CLKID_FCLK_DIV2>,
				<&mpll CLKID_MPLL2>,
				<&scmi_clk CLKID_FCLK_DIV2>;
		clock-names = "stmmaceth", "clkin0", "clkin1",
					"timing-adjustment";
		rx-fifo-depth = <4096>;
		tx-fifo-depth = <2048>;
		status = "disabled";

		mdio0: mdio {
			#address-cells = <1>;
			#size-cells = <0>;
			compatible = "snps,dwmac-mdio";
		};
	};
};

/ {
	tdmif_a: audio-controller-0 {
		compatible = "amlogic,axg-tdm-iface";
		#sound-dai-cells = <0>;
		sound-name-prefix = "TDM_A";
		clocks = <&clkc_audio AUD_CLKID_MST_A_SCLK>,
			 <&clkc_audio AUD_CLKID_MST_A_LRCLK>,
			 <&clkc_audio AUD_CLKID_MST_A_MCLK>;
		clock-names = "sclk", "lrclk","mclk";
	};

	tdmif_b: audio-controller-1 {
		compatible = "amlogic,axg-tdm-iface";
		#sound-dai-cells = <0>;
		sound-name-prefix = "TDM_B";
		clocks = <&clkc_audio AUD_CLKID_MST_B_SCLK>,
			 <&clkc_audio AUD_CLKID_MST_B_LRCLK>,
			 <&clkc_audio AUD_CLKID_MST_B_MCLK>;
		clock-names = "sclk", "lrclk","mclk";
	};

	tdmif_d: audio-controller-3 {
		compatible = "amlogic,axg-tdm-iface";
		#sound-dai-cells = <0>;
		sound-name-prefix = "TDM_D";
		clocks = <&clkc_audio AUD_CLKID_MST_D_SCLK>,
			 <&clkc_audio AUD_CLKID_MST_D_LRCLK>,
			 <&clkc_audio AUD_CLKID_MST_D_MCLK>;
		clock-names = "sclk", "lrclk", "mclk";
		status = "disabled";
	};

	tdmif_c: audio-controller-2 {
		compatible = "amlogic,axg-tdm-iface";
		#sound-dai-cells = <0>;
		sound-name-prefix = "TDM_C";
		clocks = <&clkc_audio AUD_CLKID_MST_C_SCLK>,
			 <&clkc_audio AUD_CLKID_MST_C_LRCLK>,
			 <&clkc_audio AUD_CLKID_MST_C_MCLK>;
		clock-names = "sclk", "lrclk","mclk";
	};
};

&apb4 {
	aed: audio-controller@332000 {
		compatible = "amlogic,t7-aed";
		reg = <0x0 0x332000 0x0 0x1000>;
		#sound-dai-cells = <0>;
		sound-name-prefix = "AED";
		clocks = <&clkc_audio AUD_CLKID_EQDRC>, <&clkc_audio AUD_CLKID_EQDRC_CLK>;
		clock-names = "pclk", "clk";
		power-domains = <&pwrc PWRC_T7_AUDIO_ID>;
		status = "disabled";
	};

	vad: audio-detector@331800 {
		compatible = "amlogic,t7-vad";
		reg = <0x0 0x331800 0x0 0x400>, <0x0 0x330748 0x0 0x4>;
		reg-names = "core", "feed";
		sound-name-prefix = "VAD";
		clocks = <&clkc_audio AUD_CLKID_TOVAD>, <&clkc_audio AUD_CLKID_VAD_CLK>;
		clock-names = "pclk", "clk";
		interrupts = <GIC_SPI 39 IRQ_TYPE_EDGE_RISING>;
		interrupt-names = "voice";
		power-domains = <&pwrc PWRC_T7_AUDIO_ID>;
		status = "disabled";
	};

	loopback_a: audio-controller@3302c0 {
		compatible = "amlogic,t7-loopback";
		reg = <0x0 0x3302c0 0x0 0x3c>;
		#sound-dai-cells = <0>;
		sound-name-prefix = "LOOPBACK_A";
		clocks = <&clkc_audio AUD_CLKID_LOOPBACK>;
		clock-names = "pclk";
		resets = <&clkc_audio AUD_RESET_LOOPBACK>;
		power-domains = <&pwrc PWRC_T7_AUDIO_ID>;
		status = "disabled";
	};

	loopback_b: audio-controller@3308c0 {
		compatible = "amlogic,t7-loopback";
		reg = <0x0 0x3308c0 0x0 0x3c>;
		#sound-dai-cells = <0>;
		sound-name-prefix = "LOOPBACK_B";
		clocks = <&clkc_audio AUD_CLKID_LOOPBACK_B>;
		clock-names = "pclk";
		resets = <&clkc_audio AUD_RESET_LOOPBACK_B>;
		power-domains = <&pwrc PWRC_T7_AUDIO_ID>;
		status = "disabled";
	};

	asrc_a: audio-controller@331c00 {
		compatible = "amlogic,t7-asrc-a";
		reg = <0x0 0x331c00 0x0 0x108>, <0x0 0x330d7c 0x0 0x4>;
		reg-names = "engine", "chsync";
		#sound-dai-cells = <0>;
		sound-name-prefix = "ASRC_A";
		clocks = <&clkc_audio AUD_CLKID_RESAMPLE>,
			 <&clkc_audio AUD_CLKID_MST_E_MCLK>,
			 <&clkc_audio AUD_CLKID_RESAMPLE_A_CLK>;
		clock-names = "pclk", "mclk", "clk";
		assigned-clocks = <&clkc_audio AUD_CLKID_RESAMPLE_A_SEL>;
		assigned-clock-parents = <&clkc_audio AUD_CLKID_MST_E_MCLK>;
		power-domains = <&pwrc PWRC_T7_AUDIO_ID>;
		status = "disabled";
	};

	asrc_b: audio-controller@334000 {
		compatible = "amlogic,t7-asrc-b";
		reg = <0x0 0x334000 0x0 0x108>, <0x0 0x330dbc 0x0 0x4>;
		reg-names = "engine", "chsync";
		#sound-dai-cells = <0>;
		sound-name-prefix = "ASRC_B";
		clocks = <&clkc_audio AUD_CLKID_RESAMPLE_B>,
			 <&clkc_audio AUD_CLKID_MST_F_MCLK>,
			 <&clkc_audio AUD_CLKID_RESAMPLE_B_CLK>;
		clock-names = "pclk", "mclk", "clk";
		assigned-clocks = <&clkc_audio AUD_CLKID_RESAMPLE_B_SEL>;
		assigned-clock-parents = <&clkc_audio AUD_CLKID_MST_F_MCLK>;
		power-domains = <&pwrc PWRC_T7_AUDIO_ID>;
		status = "disabled";
	};

	clkc_audio: clock-controller@330000 {
		compatible = "amlogic,t7-audio-clkc";
		reg = <0x0 0x330000 0x0 0xf0>,
			  <0x0 0x330e80 0x0 0x10>;
		#clock-cells = <1>;
		#reset-cells = <1>;
		power-domains = <&pwrc PWRC_T7_AUDIO_ID>;
		clocks = <&clkc_periphs CLKID_SYS_AUDIO>,
			 <&mpll CLKID_MPLL0>,
			 <&mpll CLKID_MPLL1>,
			 <&mpll CLKID_MPLL2>,
			 <&mpll CLKID_MPLL3>,
			 <&hifi CLKID_HIFI_PLL>,
			 <&scmi_clk CLKID_FCLK_DIV3>,
			 <&scmi_clk CLKID_FCLK_DIV4>,
			 <&scmi_clk CLKID_FCLK_DIV5>;
		clock-names = "pclk",
				  "mst_in0",
				  "mst_in1",
				  "mst_in2",
				  "mst_in3",
				  "mst_in4",
				  "mst_in5",
				  "mst_in6",
				  "mst_in7";
		resets = <&reset RESET_AUDIO>;
	};

	toddr_a: audio-controller@330100 {
		compatible = "amlogic,t7-toddr";
		reg = <0x0 0x330100 0x0 0x2c>,
		      <0x0 0x330c3c 0x0 0x4>;
		reg-names = "fifo", "chsync";
		#sound-dai-cells = <0>;
		sound-name-prefix = "TODDR_A";
		interrupts = <GIC_SPI 32 IRQ_TYPE_EDGE_RISING>;
		clocks = <&clkc_audio AUD_CLKID_TODDR_A>;
		resets = <&arb AXG_ARB_TODDR_A>,
			 <&clkc_audio AUD_RESET_TODDR_A>;
		reset-names = "arb", "rst";
		amlogic,fifo-depth = <8192>;
	};

	toddr_b: audio-controller@330140 {
		compatible = "amlogic,t7-toddr";
		reg = <0x0 0x330140 0x0 0x2c>,
		      <0x0 0x330c7c 0x0 0x4>;
		reg-names = "fifo", "chsync";
		#sound-dai-cells = <0>;
		sound-name-prefix = "TODDR_B";
		interrupts = <GIC_SPI 33 IRQ_TYPE_EDGE_RISING>;
		clocks = <&clkc_audio AUD_CLKID_TODDR_B>;
		resets = <&arb AXG_ARB_TODDR_B>,
			 <&clkc_audio AUD_RESET_TODDR_B>;
		reset-names = "arb", "rst";
		amlogic,fifo-depth = <256>;
	};

	toddr_c: audio-controller@330180 {
		compatible = "amlogic,t7-toddr";
		reg = <0x0 0x330180 0x0 0x2c>,
		      <0x0 0x330cbc 0x0 0x4>;
		reg-names = "fifo", "chsync";
		#sound-dai-cells = <0>;
		sound-name-prefix = "TODDR_C";
		interrupts = <GIC_SPI 34 IRQ_TYPE_EDGE_RISING>;
		clocks = <&clkc_audio AUD_CLKID_TODDR_C>;
		resets = <&arb AXG_ARB_TODDR_C>,
			 <&clkc_audio AUD_RESET_TODDR_C>;
		reset-names = "arb", "rst";
		amlogic,fifo-depth = <256>;
	};

	frddr_a: audio-controller@3301c0 {
		compatible = "amlogic,t7-frddr";
		reg = <0x0 0x3301c0 0x0 0x2c>;
		#sound-dai-cells = <0>;
		sound-name-prefix = "FRDDR_A";
		interrupts = <GIC_SPI 36 IRQ_TYPE_EDGE_RISING>;
		clocks = <&clkc_audio AUD_CLKID_FRDDR_A>;
		resets = <&arb AXG_ARB_FRDDR_A>,
			 <&clkc_audio AUD_RESET_FRDDR_A>;
		reset-names = "arb", "rst";
		amlogic,fifo-depth = <512>;
	};

	frddr_b: audio-controller@330200 {
		compatible = "amlogic,t7-frddr";
		reg = <0x0 0x330200 0x0 0x2c>;
		#sound-dai-cells = <0>;
		sound-name-prefix = "FRDDR_B";
		interrupts = <GIC_SPI 37 IRQ_TYPE_EDGE_RISING>;
		clocks = <&clkc_audio AUD_CLKID_FRDDR_B>;
		resets = <&arb AXG_ARB_FRDDR_B>,
			 <&clkc_audio AUD_RESET_FRDDR_B>;
		reset-names = "arb", "rst";
		amlogic,fifo-depth = <256>;
	};

	frddr_c: audio-controller@330240 {
		compatible = "amlogic,t7-frddr";
		reg = <0x0 0x330240 0x0 0x2c>;
		#sound-dai-cells = <0>;
		sound-name-prefix = "FRDDR_C";
		interrupts = <GIC_SPI 38 IRQ_TYPE_EDGE_RISING>;
		clocks = <&clkc_audio AUD_CLKID_FRDDR_C>;
		resets = <&arb AXG_ARB_FRDDR_C>,
			 <&clkc_audio AUD_RESET_FRDDR_C>;
		reset-names = "arb", "rst";
		amlogic,fifo-depth = <256>;
	};

	arb: reset-controller@330280 {
		compatible = "amlogic,meson-sm1-audio-arb";
		reg = <0x0 0x330280 0x0 0x4>;
		#reset-cells = <1>;
		clocks = <&clkc_audio AUD_CLKID_DDR_ARB>;
	};

	tdmin_a: audio-controller@330300 {
		compatible = "amlogic,t7-tdmin";
		reg = <0x0 0x330300 0x0 0x40>;
		sound-name-prefix = "TDMIN_A";
		resets = <&clkc_audio AUD_RESET_TDMIN_A>;
		clocks = <&clkc_audio AUD_CLKID_TDMIN_A>,
			 <&clkc_audio AUD_CLKID_TDMIN_A_SCLK>,
			 <&clkc_audio AUD_CLKID_TDMIN_A_SCLK_SEL>,
			 <&clkc_audio AUD_CLKID_TDMIN_A_LRCLK>,
			 <&clkc_audio AUD_CLKID_TDMIN_A_LRCLK>;
		clock-names = "pclk", "sclk", "sclk_sel",
				  "lrclk", "lrclk_sel";
	};

	tdmin_b: audio-controller@330340 {
		compatible = "amlogic,t7-tdmin";
		reg = <0x0 0x330340 0x0 0x40>;
		sound-name-prefix = "TDMIN_B";
		resets = <&clkc_audio AUD_RESET_TDMIN_B>;
		clocks = <&clkc_audio AUD_CLKID_TDMIN_B>,
			 <&clkc_audio AUD_CLKID_TDMIN_B_SCLK>,
			 <&clkc_audio AUD_CLKID_TDMIN_B_SCLK_SEL>,
			 <&clkc_audio AUD_CLKID_TDMIN_B_LRCLK>,
			 <&clkc_audio AUD_CLKID_TDMIN_B_LRCLK>;
		clock-names = "pclk", "sclk", "sclk_sel",
				  "lrclk", "lrclk_sel";
	};

	tdmin_c: audio-controller@330380 {
		compatible = "amlogic,t7-tdmin";
		reg = <0x0 0x330380 0x0 0x40>;
		sound-name-prefix = "TDMIN_C";
		resets = <&clkc_audio AUD_RESET_TDMIN_C>;
		clocks = <&clkc_audio AUD_CLKID_TDMIN_C>,
			 <&clkc_audio AUD_CLKID_TDMIN_C_SCLK>,
			 <&clkc_audio AUD_CLKID_TDMIN_C_SCLK_SEL>,
			 <&clkc_audio AUD_CLKID_TDMIN_C_LRCLK>,
			 <&clkc_audio AUD_CLKID_TDMIN_C_LRCLK>;
		clock-names = "pclk", "sclk", "sclk_sel",
				  "lrclk", "lrclk_sel";
	};

	tdmin_lb: audio-controller@3303c0 {
		compatible = "amlogic,t7-tdmin-lb";
		reg = <0x0 0x3303c0 0x0 0x40>;
		sound-name-prefix = "TDMIN_LB";
		resets = <&clkc_audio AUD_RESET_TDMIN_LB>;
		clocks = <&clkc_audio AUD_CLKID_TDMIN_LB>,
			 <&clkc_audio AUD_CLKID_TDMIN_LB_SCLK>,
			 <&clkc_audio AUD_CLKID_TDMIN_LB_SCLK_SEL>,
			 <&clkc_audio AUD_CLKID_TDMIN_LB_LRCLK>,
			 <&clkc_audio AUD_CLKID_TDMIN_LB_LRCLK>;
		clock-names = "pclk", "sclk", "sclk_sel",
				  "lrclk", "lrclk_sel";
	};

	spdifin: audio-controller@330400 {
		compatible = "amlogic,t7-spdifin";
		reg = <0x0 0x330400 0x0 0x30>;
		#sound-dai-cells = <0>;
		sound-name-prefix = "SPDIFIN";
		interrupts = <GIC_SPI 35 IRQ_TYPE_EDGE_RISING>;
		clocks = <&clkc_audio AUD_CLKID_SPDIFIN>,
		<&clkc_audio AUD_CLKID_SPDIFIN_CLK>;
		clock-names = "pclk", "refclk";
		resets = <&clkc_audio AUD_RESET_SPDIFIN>;
	};

	spdifout_a: audio-controller@330480 {
		compatible = "amlogic,t7-spdifout";
		reg = <0x0 0x330480 0x0 0x50>;
		#sound-dai-cells = <0>;
		sound-name-prefix = "SPDIFOUT_A";
		clocks = <&clkc_audio AUD_CLKID_SPDIFOUT>,
		<&clkc_audio AUD_CLKID_SPDIFOUT_CLK>;
		clock-names = "pclk", "mclk";
		resets = <&clkc_audio AUD_RESET_SPDIFOUT>;
	};

	tdmout_a: audio-controller@330500 {
		compatible = "amlogic,t7-tdmout";
		reg = <0x0 0x330500 0x0 0x40>, <0x0 0x330a80 0x0 0x38>;
		reg-names = "core", "ext";
		sound-name-prefix = "TDMOUT_A";
		resets = <&clkc_audio AUD_RESET_TDMOUT_A>;
		clocks = <&clkc_audio AUD_CLKID_TDMOUT_A>,
			 <&clkc_audio AUD_CLKID_TDMOUT_A_SCLK>,
			 <&clkc_audio AUD_CLKID_TDMOUT_A_SCLK_SEL>,
			 <&clkc_audio AUD_CLKID_TDMOUT_A_LRCLK>,
			 <&clkc_audio AUD_CLKID_TDMOUT_A_LRCLK>;
		clock-names = "pclk", "sclk", "sclk_sel",
				  "lrclk", "lrclk_sel";
	};

	tdmout_b: audio-controller@330540 {
		compatible = "amlogic,t7-tdmout";
		reg = <0x0 0x330540 0x0 0x40>, <0x0 0x330ac0 0x0 0x38>;
		reg-names = "core", "ext";
		sound-name-prefix = "TDMOUT_B";
		resets = <&clkc_audio AUD_RESET_TDMOUT_B>;
		clocks = <&clkc_audio AUD_CLKID_TDMOUT_B>,
			 <&clkc_audio AUD_CLKID_TDMOUT_B_SCLK>,
			 <&clkc_audio AUD_CLKID_TDMOUT_B_SCLK_SEL>,
			 <&clkc_audio AUD_CLKID_TDMOUT_B_LRCLK>,
			 <&clkc_audio AUD_CLKID_TDMOUT_B_LRCLK>;
		clock-names = "pclk", "sclk", "sclk_sel",
				  "lrclk", "lrclk_sel";
	};

	tdmout_c: audio-controller@330580 {
		compatible = "amlogic,t7-tdmout";
		reg = <0x0 0x330580 0x0 0x40>, <0x0 0x330b00 0x0 0x38>;
		reg-names = "core", "ext";
		sound-name-prefix = "TDMOUT_C";
		resets = <&clkc_audio AUD_RESET_TDMOUT_C>;
		clocks = <&clkc_audio AUD_CLKID_TDMOUT_C>,
			 <&clkc_audio AUD_CLKID_TDMOUT_C_SCLK>,
			 <&clkc_audio AUD_CLKID_TDMOUT_C_SCLK_SEL>,
			 <&clkc_audio AUD_CLKID_TDMOUT_C_LRCLK>,
			 <&clkc_audio AUD_CLKID_TDMOUT_C_LRCLK>;
		clock-names = "pclk", "sclk", "sclk_sel",
				  "lrclk", "lrclk_sel";
	};

	tdmin_d: audio-controller@330ec0 {
		compatible = "amlogic,t7-tdmin-d";
		reg = <0x0 0x330ec0 0x0 0x40>;
		sound-name-prefix = "TDMIN_D";
		clocks = <&clkc_audio AUD_CLKID_TDMOUT_D>,
			 <&clkc_audio AUD_CLKID_TDMIN_D_SCLK>,
			 <&clkc_audio AUD_CLKID_TDMIN_D_SCLK_SEL>,
			 <&clkc_audio AUD_CLKID_TDMIN_D_LRCLK>,
			 <&clkc_audio AUD_CLKID_TDMIN_D_LRCLK>;
		clock-names = "pclk", "sclk", "sclk_sel", "lrclk", "lrclk_sel";
		status = "disabled";
	};

	tdmout_d: audio-controller@330f40 {
		compatible = "amlogic,t7-tdmout";
		reg = <0x0 0x330f40 0x0 0x40>, <0x0 0x330f80 0x0 0x38>;
		reg-names = "core", "ext";
		sound-name-prefix = "TDMOUT_D";
		resets = <&clkc_audio AUD_RESET_TDMOUT_D>;
		clocks = <&clkc_audio AUD_CLKID_TDMOUT_D>,
			 <&clkc_audio AUD_CLKID_TDMOUT_D_SCLK>,
			 <&clkc_audio AUD_CLKID_TDMOUT_D_SCLK_SEL>,
			 <&clkc_audio AUD_CLKID_TDMOUT_D_LRCLK>,
			 <&clkc_audio AUD_CLKID_TDMOUT_D_LRCLK>;
		clock-names = "pclk", "sclk", "sclk_sel", "lrclk", "lrclk_sel";
		status = "disabled";
	};

	spdifout_b: audio-controller@330680 {
		compatible = "amlogic,t7-spdifout";
		reg = <0x0 0x330680 0x0 0x50>;
		#sound-dai-cells = <0>;
		sound-name-prefix = "SPDIFOUT_B";
		clocks = <&clkc_audio AUD_CLKID_SPDIFOUT_B>,
			 <&clkc_audio AUD_CLKID_SPDIFOUT_B_CLK>;
		clock-names = "pclk", "mclk";
		resets = <&clkc_audio AUD_RESET_SPDIFOUT_B>;
	};

	tohdmitx: audio-controller@330744 {
		compatible = "amlogic,t7-tohdmitx", "amlogic,s4-tohdmitx",
			     "amlogic,g12a-tohdmitx";
		reg = <0x0 0x330744 0x0 0x4>;
		#sound-dai-cells = <1>;
		sound-name-prefix = "TOHDMITX";
		resets = <&clkc_audio AUD_RESET_TOHDMITX>;
	};

	toddr_d: audio-controller@330840 {
		compatible = "amlogic,t7-toddr";
		reg = <0x0 0x330840 0x0 0x2c>,
		      <0x0 0x330cfc 0x0 0x4>;
		reg-names = "fifo", "chsync";
		#sound-dai-cells = <0>;
		sound-name-prefix = "TODDR_D";
		interrupts = <GIC_SPI 45 IRQ_TYPE_EDGE_RISING>;
		clocks = <&clkc_audio AUD_CLKID_TODDR_D>;
		resets = <&arb AXG_ARB_TODDR_D>,
			 <&clkc_audio AUD_RESET_TODDR_D>;
		reset-names = "arb", "rst";
		amlogic,fifo-depth = <256>;
	};

	frddr_d: audio-controller@330880 {
		compatible = "amlogic,t7-frddr";
		reg = <0x0 0x330880 0x0 0x2c>;
		#sound-dai-cells = <0>;
		sound-name-prefix = "FRDDR_D";
		interrupts = <GIC_SPI 46 IRQ_TYPE_EDGE_RISING>;
		clocks = <&clkc_audio AUD_CLKID_FRDDR_D>;
		resets = <&arb AXG_ARB_FRDDR_D>,
			 <&clkc_audio AUD_RESET_FRDDR_D>;
		reset-names = "arb", "rst";
		amlogic,fifo-depth = <256>;
	};

	pdm: audio-controller@331000 {
		compatible = "amlogic,t7-pdm",
			     "amlogic,axg-pdm";
		reg = <0x0 0x331000 0x0 0x34>;
		#sound-dai-cells = <0>;
		sound-name-prefix = "PDM";
		clocks = <&clkc_audio AUD_CLKID_PDM>,
			 <&clkc_audio AUD_CLKID_PDM_DCLK>,
			 <&clkc_audio AUD_CLKID_PDM_SYSCLK>;
		clock-names = "pclk", "dclk", "sysclk";
		resets = <&clkc_audio AUD_RESET_PDM>;
	};
};

/ {
	vpu: vpu@ff000000 {
		compatible = "amlogic,meson-t7-vpu";
		reg = <0x0 0xff000000 0x0 0x40000>,
		      <0x0 0xfe008000 0x0 0x2000>,
		      <0x0 0xfe000000 0x0 0x2000>,
		      <0x0 0xfe00c000 0x0 0x800>,
		      <0x0 0xfe010000 0x0 0x100>;
		reg-names = "vpu", "hhi", "clkctrl", "pwrctrl", "sysctrl";
		interrupts = <GIC_SPI 197 IRQ_TYPE_EDGE_RISING>;
		amlogic,canvas = <&canvas>;
		power-domains = <&pwrc PWRC_T7_VPU_HDMI_ID>;
		clocks = <&clkc_periphs CLKID_SYS_VPU_INTR>;
		clock-names = "intr";
		#address-cells = <1>;
		#size-cells = <0>;
		status = "disabled";

		/* CVBS VDAC output port */
		cvbs_vdac_port: port@0 {
			reg = <0>;
		};

		/* HDMI-TX output port */
		hdmi_tx_port: port@1 {
			reg = <1>;

			hdmi_tx_out: endpoint {
				remote-endpoint = <&hdmi_tx_in>;
			};
		};
	};
};

&apb4 {
	canvas: video-lut@36048 {
		compatible = "amlogic,canvas";
		reg = <0x0 0x36048 0x0 0x14>;
	};

	/* Experimental decoder: normal boards retain the tested encode paths. */
	vdec: video-codec@320000 {
		compatible = "amlogic,t7-vcodec-dec";
		reg = <0x0 0x320000 0x0 0x10000>;
		reg-names = "dos";
		interrupts = <GIC_SPI 92 IRQ_TYPE_EDGE_RISING>;
		clocks = <&clkc_periphs CLKID_SYS_DOS>,
			 <&clkc_periphs CLKID_VDEC>,
			 <&clkc_periphs CLKID_SYS_PCLK_SYS_APB>,
			 <&clkc_periphs CLKID_SYS_A73PCLK_APB>,
			 <&clkc_periphs CLKID_VDEC_0>;
		clock-names = "vdec", "clk_vdec_mux", "sys-apb", "a73-apb", "vdec-p0";
		/* Secure firmware owns VDEC RAM/isolation/reset; NIC3 is its parent. */
		power-domains = <&pwrc PWRC_T7_DOS_VDEC_ID>,
				<&pwrc PWRC_T7_NIC3_ID>;
		power-domain-names = "vdec", "nic3";
		amlogic,canvas = <&canvas>;
		status = "disabled";
	};

	hdmirx: hdmi-receiver@398000 {
		compatible = "amlogic,t7-hdmirx";
		amlogic,input-port = <0>;
		reg = <0x0 0x398000 0x0 0x4000>,
		      <0x0 0x39c000 0x0 0x50>,
		      <0x0 0x3a0000 0x0 0x8000>;
		reg-names = "top", "phy", "cor";
		power-domains = <&pwrc PWRC_T7_HDMIRX_ID>;
		clocks = <&clkc_periphs CLKID_SYS_HDMIRX_PCLK>,
			 <&clkc_periphs CLKID_SYS_HDMIRX>,
			 <&clkc_periphs CLKID_HDMIRX_CFG>,
			 <&clkc_periphs CLKID_HDMIRX_METER>,
			 <&clkc_periphs CLKID_HDMIRX_2M>,
			 <&clkc_periphs CLKID_HDMIRX_5M>;
		clock-names = "pclk", "sys", "cfg", "meter", "2m", "5m";
		status = "disabled";
	};

	hdmi_tx: hdmi-tx@300000 {
		compatible = "amlogic,t7-hdmi-tx";
		reg = <0x0 0x300000 0x0 0x10000>,
		      <0x0 0x380000 0x0 0x10000>;
		reg-names = "top", "cor";
		interrupts = <GIC_SPI 204 IRQ_TYPE_LEVEL_HIGH>;
		power-domains = <&pwrc PWRC_T7_VI_CLK2_ID>;
		clocks = <&clkc_periphs CLKID_SYS_HDMITX_APB>;
		clock-names = "pclk";
		resets = <&reset RESET_HDMITX>,
			 <&reset RESET_HDMITXPHY>;
		reset-names = "hdmitx", "phy";
		#sound-dai-cells = <0>;
		hpd-gpios = <&gpio GPIOW_15 GPIO_ACTIVE_HIGH>;
		pinctrl-0 = <&hdmitx_ddc_pins>;
		pinctrl-names = "default";
		status = "disabled";

		ports {
			#address-cells = <1>;
			#size-cells = <0>;

			port@0 {
				reg = <0>;

				hdmi_tx_in: endpoint {
					remote-endpoint = <&hdmi_tx_out>;
				};
			};

			port@1 {
				reg = <1>;

				hdmi_tx_tmds_out: endpoint {
				};
			};
		};
	};
};

&periphs_pinctrl {
	ir_pins: ir-pins {
		mux {
			groups = "remote_in";
			function = "remote_in";
			bias-disable;
		};
	};

	spifc_pins: spifc-pins {
		mux {
			groups = "nor_hold", "nor_d", "nor_q", "nor_c",
				 "nor_wp", "nor_cs";
			function = "nor";
		};
	};

	hdmitx_hpd_pins: hdmitx-hpd {
		mux {
			groups = "hdmitx_hpd_in";
			function = "hdmitx";
			bias-disable;
		};
	};

	hdmitx_ddc_pins: hdmitx-ddc {
		mux {
			groups = "hdmitx_sda_w13",
				 "hdmitx_sck_w14";
			function = "hdmitx";
			bias-disable;
			drive-strength-microamp = <4000>;
		};
	};
};
